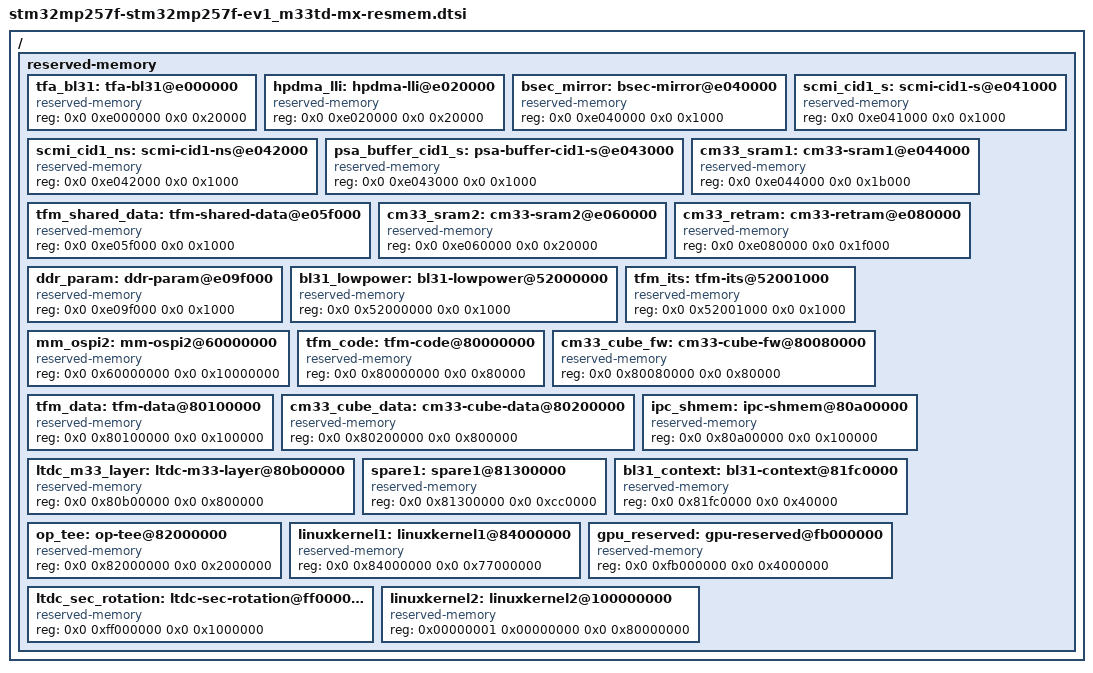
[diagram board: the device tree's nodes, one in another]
// SPDX-License-Identifier: (GPL-2.0-or-later OR BSD-3-Clause)
/*
 * Copyright (C) 2025, STMicroelectronics - All Rights Reserved
 * Author: STM32CubeMX code generation for STMicroelectronics.
 */

/* For more information on Device Tree configuration, please refer to
 * https://wiki.st.com/stm32mpu/wiki/Category:Device_tree_configuration
 */

 / {

	reserved-memory{

		#address-cells = <2>;
		#size-cells = <2>;
		ranges;

		tfa_bl31: tfa-bl31@e000000 {
			compatible = "reserved-memory";
			reg = <0x0 0xe000000 0x0 0x20000>;
			#memory-region-cells = <0>;

			/* USER CODE BEGIN tfa_bl31 */
			/* USER CODE END tfa_bl31 */
		};

		hpdma_lli: hpdma-lli@e020000 {
			compatible = "reserved-memory";
			reg = <0x0 0xe020000 0x0 0x20000>;
			#memory-region-cells = <0>;

			/* USER CODE BEGIN hpdma_lli */
			/* USER CODE END hpdma_lli */
		};

		bsec_mirror: bsec-mirror@e040000 {
			compatible = "reserved-memory";
			reg = <0x0 0xe040000 0x0 0x1000>;
			#memory-region-cells = <0>;

			/* USER CODE BEGIN bsec_mirror */
			/* USER CODE END bsec_mirror */
		};

		scmi_cid1_s: scmi-cid1-s@e041000 {
			compatible = "reserved-memory";
			reg = <0x0 0xe041000 0x0 0x1000>;
			#memory-region-cells = <0>;

			/* USER CODE BEGIN scmi_cid1_s */
			/* USER CODE END scmi_cid1_s */
		};

		scmi_cid1_ns: scmi-cid1-ns@e042000 {
			compatible = "reserved-memory";
			reg = <0x0 0xe042000 0x0 0x1000>;
			#memory-region-cells = <0>;

			/* USER CODE BEGIN scmi_cid1_ns */
			/* USER CODE END scmi_cid1_ns */
		};

		psa_buffer_cid1_s: psa-buffer-cid1-s@e043000 {
			compatible = "reserved-memory";
			reg = <0x0 0xe043000 0x0 0x1000>;
			#memory-region-cells = <0>;

			/* USER CODE BEGIN psa_buffer_cid1_s */
			/* USER CODE END psa_buffer_cid1_s */
		};

		cm33_sram1: cm33-sram1@e044000 {
			compatible = "reserved-memory";
			reg = <0x0 0xe044000 0x0 0x1b000>;
			#memory-region-cells = <0>;

			/* USER CODE BEGIN cm33_sram1 */
			/* USER CODE END cm33_sram1 */
		};

		tfm_shared_data: tfm-shared-data@e05f000 {
			compatible = "reserved-memory";
			reg = <0x0 0xe05f000 0x0 0x1000>;
			#memory-region-cells = <0>;

			/* USER CODE BEGIN tfm_shared_data */
			/* USER CODE END tfm_shared_data */
		};

		cm33_sram2: cm33-sram2@e060000 {
			compatible = "reserved-memory";
			reg = <0x0 0xe060000 0x0 0x20000>;
			#memory-region-cells = <0>;

			/* USER CODE BEGIN cm33_sram2 */
			/* USER CODE END cm33_sram2 */
		};

		cm33_retram: cm33-retram@e080000 {
			compatible = "reserved-memory";
			reg = <0x0 0xe080000 0x0 0x1f000>;
			#memory-region-cells = <0>;

			/* USER CODE BEGIN cm33_retram */
			/* USER CODE END cm33_retram */
		};

		ddr_param: ddr-param@e09f000 {
			compatible = "reserved-memory";
			reg = <0x0 0xe09f000 0x0 0x1000>;
			#memory-region-cells = <0>;

			/* USER CODE BEGIN ddr_param */
			/* USER CODE END ddr_param */
		};

		bl31_lowpower: bl31-lowpower@52000000 {
			compatible = "reserved-memory";
			reg = <0x0 0x52000000 0x0 0x1000>;
			#memory-region-cells = <0>;

			/* USER CODE BEGIN bl31_lowpower */
			/* USER CODE END bl31_lowpower */
		};

		tfm_its: tfm-its@52001000 {
			compatible = "reserved-memory";
			reg = <0x0 0x52001000 0x0 0x1000>;
			#memory-region-cells = <0>;

			/* USER CODE BEGIN tfm_its */
			/* USER CODE END tfm_its */
		};

		mm_ospi2: mm-ospi2@60000000 {
			compatible = "reserved-memory";
			reg = <0x0 0x60000000 0x0 0x10000000>;
			#memory-region-cells = <0>;

			/* USER CODE BEGIN mm_ospi */
			/* USER CODE END mm_ospi */
		};

		tfm_code: tfm-code@80000000 {
			compatible = "reserved-memory";
			reg = <0x0 0x80000000 0x0 0x80000>;
			#memory-region-cells = <0>;

			/* USER CODE BEGIN tfm_code */
			/* USER CODE END tfm_code */
		};

		cm33_cube_fw: cm33-cube-fw@80080000 {
			compatible = "reserved-memory";
			reg = <0x0 0x80080000 0x0 0x80000>;
			#memory-region-cells = <0>;

			/* USER CODE BEGIN cm33_cube_fw */
			/* USER CODE END cm33_cube_fw */
		};

		tfm_data: tfm-data@80100000 {
			compatible = "reserved-memory";
			reg = <0x0 0x80100000 0x0 0x100000>;
			#memory-region-cells = <0>;

			/* USER CODE BEGIN tfm_data */
			/* USER CODE END tfm_data */
		};

		cm33_cube_data: cm33-cube-data@80200000 {
			compatible = "reserved-memory";
			reg = <0x0 0x80200000 0x0 0x800000>;
			#memory-region-cells = <0>;

			/* USER CODE BEGIN cm33_cube_data */
			/* USER CODE END cm33_cube_data */
		};

		ipc_shmem: ipc-shmem@80a00000 {
			compatible = "reserved-memory";
			reg = <0x0 0x80a00000 0x0 0x100000>;
			#memory-region-cells = <0>;

			/* USER CODE BEGIN ipc_shmem */
			/* USER CODE END ipc_shmem */
		};

		ltdc_m33_layer: ltdc-m33-layer@80b00000 {
			compatible = "reserved-memory";
			reg = <0x0 0x80b00000 0x0 0x800000>;
			#memory-region-cells = <0>;

			/* USER CODE BEGIN ltdc_m33_layer */
			/* USER CODE END ltdc_m33_layer */
		};

		spare1: spare1@81300000 {
			compatible = "reserved-memory";
			reg = <0x0 0x81300000 0x0 0xcc0000>;
			#memory-region-cells = <0>;

			/* USER CODE BEGIN spare1 */
			/* USER CODE END spare1 */
		};

		bl31_context: bl31-context@81fc0000 {
			compatible = "reserved-memory";
			reg = <0x0 0x81fc0000 0x0 0x40000>;
			#memory-region-cells = <0>;

			/* USER CODE BEGIN bl31_context */
			/* USER CODE END bl31_context */
		};

		op_tee: op-tee@82000000 {
			compatible = "reserved-memory";
			reg = <0x0 0x82000000 0x0 0x2000000>;
			#memory-region-cells = <0>;

			/* USER CODE BEGIN op_tee */
			/* USER CODE END op_tee */
		};

		linuxkernel1: linuxkernel1@84000000 {
			compatible = "reserved-memory";
			reg = <0x0 0x84000000 0x0 0x77000000>;
			#memory-region-cells = <0>;

			/* USER CODE BEGIN linuxkernel1 */
			/* USER CODE END linuxkernel1 */
		};

		gpu_reserved: gpu-reserved@fb000000 {
			compatible = "reserved-memory";
			reg = <0x0 0xfb000000 0x0 0x4000000>;
			#memory-region-cells = <0>;

			/* USER CODE BEGIN gpu_reserved */
			/* USER CODE END gpu_reserved */
		};

		ltdc_sec_rotation: ltdc-sec-rotation@ff000000 {
			compatible = "reserved-memory";
			reg = <0x0 0xff000000 0x0 0x1000000>;
			#memory-region-cells = <0>;

			/* USER CODE BEGIN ltdc_sec_rotation */
			/* USER CODE END ltdc_sec_rotation */
		};

		linuxkernel2: linuxkernel2@100000000 {
			compatible = "reserved-memory";
			reg = <0x00000001 0x00000000 0x0 0x80000000>;
			#memory-region-cells = <0>;

			/* USER CODE BEGIN linuxkernel2 */
			/* USER CODE END linuxkernel2 */
		};

		/* USER CODE BEGIN reserved-memory */
		/* USER CODE END reserved-memory */
	};
};
